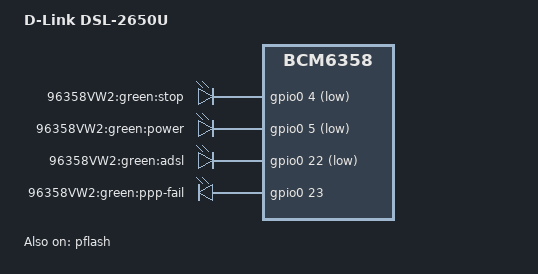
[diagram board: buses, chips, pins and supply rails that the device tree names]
/dts-v1/;

/include/ "bcm6358.dtsi"

/ {
	model = "D-Link DSL-2650U";
	compatible = "d-link,dsl-2650u", "brcm,bcm6358";

	gpio-leds {
		compatible = "gpio-leds";

		stop_green {
			label = "96358VW2:green:stop";
			gpios = <&gpio0 4 1>;
		};
		power_green {
			label = "96358VW2:green:power";
			gpios = <&gpio0 5 1>;
			default-state = "on";
		};
		adsl_green {
			label = "96358VW2:green:adsl";
			gpios = <&gpio0 22 1>;
		};
		ppp_fail_green {
			label = "96358VW2:green:ppp-fail";
			gpios = <&gpio0 23 0>;
		};
	};
};

&pflash {
	status = "ok";

	linux,part-probe = "bcm63xxpart";

	cfe@0 {
		label = "CFE";
		reg = <0x000000 0x010000>;
		read-only;
	};

	linux@10000 {
		label = "linux";
		reg = <0x010000 0x7e0000>;
	};

	nvram@7f0000 {
		label = "nvram";
		reg = <0x7f0000 0x010000>;
	};
};
